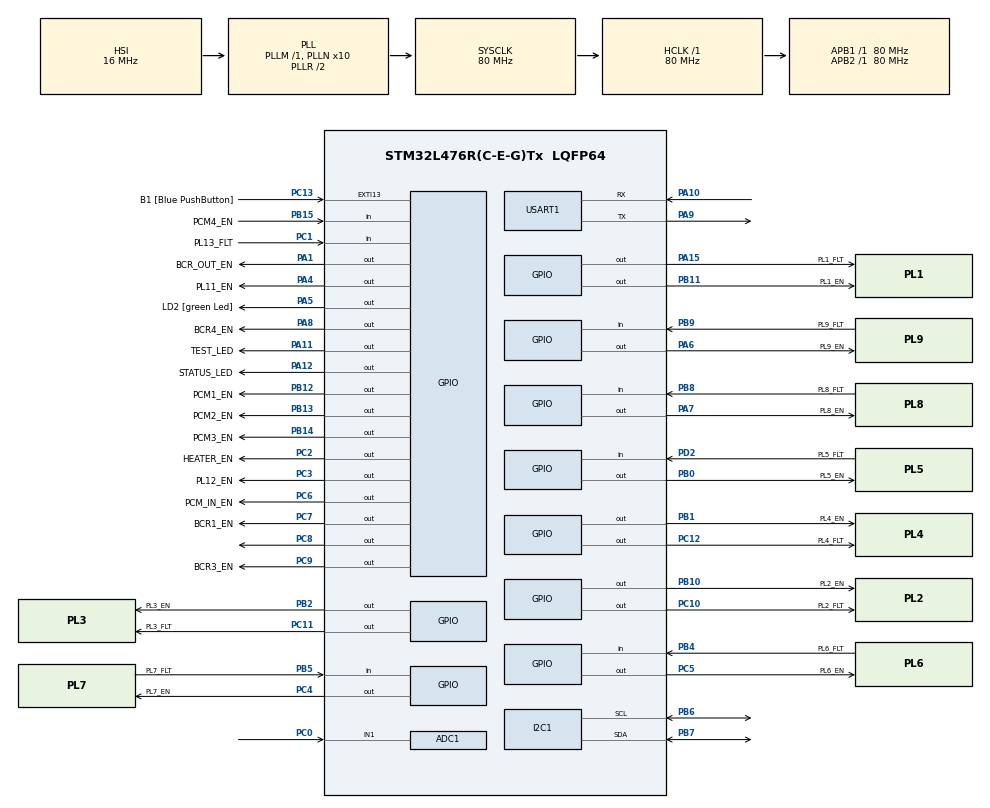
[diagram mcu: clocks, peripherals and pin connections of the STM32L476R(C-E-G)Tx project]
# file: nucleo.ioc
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ADC1.Channel-0\#ChannelRegularConversion=ADC_CHANNEL_1
ADC1.NbrOfConversionFlag=1
ADC1.OffsetNumber-0\#ChannelRegularConversion=ADC_OFFSET_NONE
ADC1.Rank-0\#ChannelRegularConversion=1
ADC1.SamplingTime-0\#ChannelRegularConversion=ADC_SAMPLETIME_2CYCLES_5
ADC1.master=1
Mcu.Family=STM32L4
Mcu.Name=STM32L476R(C-E-G)Tx
Mcu.Package=LQFP64
NVIC.PriorityGroup=NVIC_PRIORITYGROUP_4
PA0.Mode=SYS_WakeUp0
PA0.Signal=SYS_WKUP1
PA1.GPIO_Label=BCR_OUT_EN
PA1.Signal=GPIO_Output
PA10.Mode=Asynchronous
PA10.Signal=USART1_RX
PA11.GPIO_Label=TEST_LED
PA11.Signal=GPIO_Output
PA12.GPIO_Label=STATUS_LED
PA12.Signal=GPIO_Output
PA13.GPIO_Label=TMS
PA13.Signal=SYS_JTMS-SWDIO
PA14.GPIO_Label=TCK
PA14.Signal=SYS_JTCK-SWCLK
PA15.GPIO_Label=PL1_FLT
PA15.Signal=GPIO_Output
PA2.GPIO_Label=USART_TX
PA2.GPIO_Mode=GPIO_MODE_AF_PP
PA2.GPIO_PuPd=GPIO_NOPULL
PA2.GPIO_Speed=GPIO_SPEED_FREQ_VERY_HIGH
PA2.Signal=USART2_TX
PA3.GPIO_Label=USART_RX
PA3.GPIO_Mode=GPIO_MODE_AF_PP
PA3.GPIO_PuPd=GPIO_NOPULL
PA3.GPIO_Speed=GPIO_SPEED_FREQ_VERY_HIGH
PA3.Signal=USART2_RX
PA4.GPIO_Label=PL11_EN
PA4.Signal=GPIO_Output
PA5.GPIO_Label=LD2 [green Led]
PA5.GPIO_ModeDefaultOutputPP=GPIO_MODE_OUTPUT_PP
PA5.GPIO_PuPd=GPIO_NOPULL
PA5.GPIO_Speed=GPIO_SPEED_FREQ_LOW
PA5.Signal=GPIO_Output
PA6.GPIO_Label=PL9_EN
PA6.Signal=GPIO_Output
PA7.GPIO_Label=PL8_EN
PA7.Signal=GPIO_Output
PA8.GPIO_Label=BCR4_EN
PA8.Signal=GPIO_Output
PA9.Mode=Asynchronous
PA9.Signal=USART1_TX
PB0.GPIO_Label=PL5_EN
PB0.Signal=GPIO_Output
PB1.GPIO_Label=PL4_EN
PB1.Signal=GPIO_Output
PB10.GPIO_Label=PL2_EN
PB10.Signal=GPIO_Output
PB11.GPIO_Label=PL1_EN
PB11.Signal=GPIO_Output
PB12.GPIO_Label=PCM1_EN
PB12.Signal=GPIO_Output
PB13.GPIO_Label=PCM2_EN
PB13.Signal=GPIO_Output
PB14.GPIO_Label=PCM3_EN
PB14.Signal=GPIO_Output
PB15.GPIO_Label=PCM4_EN
PB15.Signal=GPIO_Input
PB2.GPIO_Label=PL3_EN
PB2.Signal=GPIO_Output
PB3.GPIO_Label=SWO
PB3.Signal=SYS_JTDO-SWO
PB4.GPIO_Label=PL6_FLT
PB4.Signal=GPIO_Input
PB5.GPIO_Label=PL7_FLT
PB5.Signal=GPIO_Input
PB6.Mode=I2C
PB6.Signal=I2C1_SCL
PB7.Mode=I2C
PB7.Signal=I2C1_SDA
PB8.GPIO_Label=PL8_FLT
PB8.Signal=GPIO_Input
PB9.GPIO_Label=PL9_FLT
PB9.Signal=GPIO_Input
PC0.Signal=ADCx_IN1
PC1.GPIO_Label=PL13_FLT
PC1.Signal=GPIO_Input
PC10.GPIO_Label=PL2_FLT
PC10.Signal=GPIO_Output
PC11.GPIO_Label=PL3_FLT
PC11.Signal=GPIO_Output
PC12.GPIO_Label=PL4_FLT
PC12.Signal=GPIO_Output
PC13.GPIO_Label=B1 [Blue PushButton]
PC13.GPIO_ModeDefaultEXTI=GPIO_MODE_IT_FALLING
PC13.GPIO_PuPd=GPIO_NOPULL
PC13.Signal=GPXTI13
PC14/OSC32_IN.Signal=RCC_OSC32_IN
PC15/OSC32_OUT.Signal=RCC_OSC32_OUT
PC2.GPIO_Label=HEATER_EN
PC2.Signal=GPIO_Output
PC3.GPIO_Label=PL12_EN
PC3.Signal=GPIO_Output
PC4.GPIO_Label=PL7_EN
PC4.Signal=GPIO_Output
PC5.GPIO_Label=PL6_EN
PC5.Signal=GPIO_Output
PC6.GPIO_Label=PCM_IN_EN
PC6.Signal=GPIO_Output
PC7.GPIO_Label=BCR1_EN
PC7.Signal=GPIO_Output
PC8.Signal=GPIO_Output
PC9.GPIO_Label=BCR3_EN
PC9.Signal=GPIO_Output
PD2.GPIO_Label=PL5_FLT
PD2.Signal=GPIO_Input
PH0/OSC_IN.Signal=RCC_OSC_IN
PH1/OSC_OUT.Signal=RCC_OSC_OUT
ProjectManager.HeapSize=0x200
ProjectManager.StackSize=0x400
ProjectManager.TargetToolchain=MDK-ARM V5
RCC.ADCFreq_Value=64000000
RCC.AHBFreq_Value=80000000
RCC.APB1Freq_Value=80000000
RCC.APB1TimFreq_Value=80000000
RCC.APB2Freq_Value=80000000
RCC.APB2TimFreq_Value=80000000
RCC.CortexFreq_Value=80000000
RCC.HCLKFreq_Value=80000000
RCC.HSE_VALUE=8000000
RCC.HSI_VALUE=16000000
RCC.LSE_VALUE=32768
RCC.MSI_VALUE=4000000
RCC.PLLN=10
RCC.PLLSourceVirtual=RCC_PLLSOURCE_HSI
RCC.PREFETCH_ENABLE=1
RCC.SYSCLKFreq_VALUE=80000000
RCC.SYSCLKSource=RCC_SYSCLKSOURCE_PLLCLK
RCC.USBFreq_Value=64000000
RCC.VCOOutputFreq_Value=160000000
SH.ADCx_IN1.0=ADC1_IN1,IN1-Single-Ended
USART1.VirtualMode-Asynchronous=VM_ASYNC
board=NUCLEO-L476RG

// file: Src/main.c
/*SEDS TRITEIA POWER SYSTEMS TEAM prototype EPS code
 *C code to implement EPS protection Schemes
 *STM32 version 0.0.1
 *Authored by Jordan Prazak and David TU
 *
 */

/**
  ******************************************************************************
  * File Name          : main.c
  * Description        : Main program body
  ******************************************************************************
  *
  * COPYRIGHT(c) 2017 STMicroelectronics
  *
  * Redistribution and use in source and binary forms, with or without modification,
  * are permitted provided that the following conditions are met:
  *   1. Redistributions of source code must retain the above copyright notice,
  *      this list of conditions and the following disclaimer.
  *   2. Redistributions in binary form must reproduce the above copyright notice,
  *      this list of conditions and the following disclaimer in the documentation
  *      and/or other materials provided with the distribution.
  *   3. Neither the name of STMicroelectronics nor the names of its contributors
  *      may be used to endorse or promote products derived from this software
  *      without specific prior written permission.
  *
  * THIS SOFTWARE IS PROVIDED BY THE COPYRIGHT HOLDERS AND CONTRIBUTORS "AS IS"
  * AND ANY EXPRESS OR IMPLIED WARRANTIES, INCLUDING, BUT NOT LIMITED TO, THE
  * IMPLIED WARRANTIES OF MERCHANTABILITY AND FITNESS FOR A PARTICULAR PURPOSE ARE
  * DISCLAIMED. IN NO EVENT SHALL THE COPYRIGHT HOLDER OR CONTRIBUTORS BE LIABLE
  * FOR ANY DIRECT, INDIRECT, INCIDENTAL, SPECIAL, EXEMPLARY, OR CONSEQUENTIAL
  * DAMAGES (INCLUDING, BUT NOT LIMITED TO, PROCUREMENT OF SUBSTITUTE GOODS OR
  * SERVICES; LOSS OF USE, DATA, OR PROFITS; OR BUSINESS INTERRUPTION) HOWEVER
  * CAUSED AND ON ANY THEORY OF LIABILITY, WHETHER IN CONTRACT, STRICT LIABILITY,
  * OR TORT (INCLUDING NEGLIGENCE OR OTHERWISE) ARISING IN ANY WAY OUT OF THE USE
  * OF THIS SOFTWARE, EVEN IF ADVISED OF THE POSSIBILITY OF SUCH DAMAGE.
  *
  ******************************************************************************
  */
#include "main.h"
#include "stm32l4xx_hal.h"

/*EPS includes ---------------------------------------------------------------*/
#include "INA260.h"
#include "EPS.h"

ADC_HandleTypeDef hadc1;

I2C_HandleTypeDef hi2c1;

UART_HandleTypeDef huart1;

void SystemClock_Config(void);
void Error_Handler(void);
static void MX_GPIO_Init(void);
static void MX_I2C1_Init(void);
static void MX_ADC1_Init(void);
static void MX_USART1_UART_Init(void);

//TODO add correct indexes for INA260 current and voltage monitoring chips
int main(void)
{
  /* MCU Configuration--------------------------------------------------------*/

  /* Reset of all peripherals, Initializes the Flash interface and the Systick*/
  HAL_Init();

  /* Configure the system clock */
  SystemClock_Config();

  /* Initialize all configured peripherals */
  MX_GPIO_Init();
  MX_I2C1_Init();
  MX_ADC1_Init();
  MX_USART1_UART_Init();

  /* Turn on LD2 */
  HAL_GPIO_WritePin(GPIOA, LD2_Pin, GPIO_PIN_SET);

	/*Initialize System --------------------------------------------------------*/
	//init variables
	// Boolean to determine whether to send data (stream) to CHREC processor
	int i;
	unsigned int streamenabled;
	EPS_status_t EPS_status;

	//configure IV monitors
 	sendConfig( &hi2c1,0);
	sendConfig( &hi2c1,1);
	sendConfig( &hi2c1,2);
	sendConfig( &hi2c1,3);
	sendConfig( &hi2c1,4);
	sendConfig( &hi2c1,5);
	sendConfig( &hi2c1,6);
	sendConfig( &hi2c1,7);
	sendConfig( &hi2c1,8);
	sendConfig( &hi2c1,9);

/*******************************************************************************
*                          EPS Power-on sequence                               *
*******************************************************************************/

	// Measure battery voltage until it comes into an acceptable range
	do {
		sendConfig( &hi2c1,0);
		EPS_status.batt_v = getVoltage(&hi2c1,0);
	} while(EPS_status.batt_v < DEPLOYED_BATT_LOW || EPS_status.batt_v > DEPLOYED_BATT_HIGH );

	// Next, check to see if there is voltage and current coming from one of the
	// solar panels. If so, the cubesat is deployed.
	do {
		sendConfig( &hi2c1,0);
		EPS_status.solar1_i = getCurrent(&hi2c1,0);
		EPS_status.solar1_v = getVoltage(&hi2c1,0);

		sendConfig( &hi2c1,0);
		EPS_status.solar2_i = getCurrent(&hi2c1,0);
		EPS_status.solar2_v = getVoltage(&hi2c1,0);

		sendConfig( &hi2c1,0);
		EPS_status.solar3_i = getCurrent(&hi2c1,0);
		EPS_status.solar3_v = getVoltage(&hi2c1,0);

		sendConfig( &hi2c1,0);
		EPS_status.solar4_i = getCurrent(&hi2c1,0);
		EPS_status.solar4_v = getVoltage(&hi2c1,0);

	} while(
			( EPS_status.solar1_v > DEPLOYED_SOLAR_V && EPS_status.solar1_i > DEPLOYED_SOLAR_I ) ||
			( EPS_status.solar2_v > DEPLOYED_SOLAR_V && EPS_status.solar2_i > DEPLOYED_SOLAR_I ) ||
			( EPS_status.solar3_v > DEPLOYED_SOLAR_V && EPS_status.solar3_i > DEPLOYED_SOLAR_I ) ||
			( EPS_status.solar4_v > DEPLOYED_SOLAR_V && EPS_status.solar4_i > DEPLOYED_SOLAR_I )
			 );

	// Cubesat has been successfully deployed. Wait at least 15 seconds, and
	// then power on all the loads.
	HAL_DELAY(15000);

	HAL_GPIO_WritePin(GPIOC, PCM_IN_EN_Pin, GPIO_PIN_SET); //enable EPS output

	}

/*******************************************************************************
*             Voltage, Current, and Temperature Monitoring                     *
*******************************************************************************/

		// Trigger a measurement on the IV monitors
 		sendConfig( &hi2c1,0);
		sendConfig( &hi2c1,1);
		sendConfig( &hi2c1,2);
		sendConfig( &hi2c1,3);
		sendConfig( &hi2c1,4);
		sendConfig( &hi2c1,5);
		sendConfig( &hi2c1,6);
		sendConfig( &hi2c1,7);
		sendConfig( &hi2c1,8);
		sendConfig( &hi2c1,9);
 		HAL_DELAY(CONVERSION_TIME_INA3221);

		EPS_status.solar1_i = getCurrent(&hi2c1,0);
		EPS_status.solar1_v = getVoltage(&hi2c1,0);

    batt_temp = (float) mmap_adc_read_raw( 0 ) * 1.8 * 1000000 / 4095 / 994 - 273.2 + TEMP_CALIBRATION;

    // Current conversion: i * 0.04/(8*2)
    // Voltage conversion: v * 0.008/8
    // 28V rail, current & voltage: i or v * 0.00125

    /**************************************************************************
     *                       Battery: Over-voltage Check                      *
     **************************************************************************/

    // If battery voltage is too high, open BCR switch
    if( batt_iv.v > BATT_OVER_VOLTAGE ) {
      gpio_set_value( BCR_OUT_EN, 0 );
    }
    else {

      // TODO we need to figure out a turn-on BCR voltage after over voltage
      gpio_set_value( BCR_OUT_EN, 1 );
    }

    /**************************************************************************
     *                       Battery: Under-voltage Check                     *
     **************************************************************************/

     // If battery voltage is too low, open PCM switch
      if( batt_iv.v < BATT_UNDER_VOLTAGE ) {
        i = 0;
        while( PDM_EN[i] != NULL ) {
          gpio_set_value( PDM_EN[i++], LOW );
        }
      }
      else {

        // TODO we need to figure out a turn-on PCM after under voltage
        i = 0;
        while( PDM_EN[i] != NULL ) {
          gpio_set_value( PDM_EN[i++], HIGH );
        }
      }

    /**************************************************************************
     *                     Power Rails: Over-current Check                    *
     **************************************************************************/

     // TODO
     // So technically, we have control of every payload.
     // Since the re-latching time is very quick, it will have no effect with
     // the 1 Hz loop code checking 3 times (3 seconds). We will need an
     // internal static counter. If after 3 seconds it's still latched, we have
     // a permanent fault.

     i = 0;
     while( PDM_FAULT[i] != NULL ) {
       if( gpio_get_value( PDM_FAULT[i] ) != 0 ) {
         if( faults[i].fault_count < 3 ) {
           // Attempt to unlatch
           gpio_set_value( PDM_EN[i], 0 );
     			 usleep( 1000 );
     			 gpio_set_value( PDM_EN[i], 1 );
           faults[i].fault_count += 1;
         }
         else {
           // PERMANENT FAULT! TODO SEND TO MISSION CONTROL! But only do it once.
           gpio_set_value( PDM_EN[i], 0 );
         }
       }
       else {
         faults[i].fault_count = 0;
       }
       i += 1;
     }

    /**************************************************************************
     *                       Battery Temperature Check                        *
     **************************************************************************/

      // If the battery temperature is too low, turn on heater until the
      // desired temperature is reached.
      if( batt_temp < HEATER_ON_TEMP ) {
        gpio_set_value( HEATER_EN, 1 );
      }
      else if( batt_temp > HEATER_OFF_TEMP ) {
        gpio_set_value( HEATER_EN, 0 );
      }

    /**************************************************************************
     *                     Sending Data to CHREC processor                    *
     **************************************************************************/
  	//send data is unused for the subsystem prototype
      // if the stream is enabled, send data to CHREK processor
      //this process may run on a separate timer instead
      //if (streamenabled==1)
          //send_data();

    // Sample at a rate of 1 Hz
  	usleep(1000000);
  }

  return EXIT_SUCCESS;
}
}
/** System Clock Configuration
*/
void SystemClock_Config(void)
{

  RCC_OscInitTypeDef RCC_OscInitStruct;
  RCC_ClkInitTypeDef RCC_ClkInitStruct;
  RCC_PeriphCLKInitTypeDef PeriphClkInit;

    /**Initializes the CPU, AHB and APB busses clocks
    */
  RCC_OscInitStruct.OscillatorType = RCC_OSCILLATORTYPE_HSI;
  RCC_OscInitStruct.HSIState = RCC_HSI_ON;
  RCC_OscInitStruct.HSICalibrationValue = 16;
  RCC_OscInitStruct.PLL.PLLState = RCC_PLL_ON;
  RCC_OscInitStruct.PLL.PLLSource = RCC_PLLSOURCE_HSI;
  RCC_OscInitStruct.PLL.PLLM = 1;
  RCC_OscInitStruct.PLL.PLLN = 10;
  RCC_OscInitStruct.PLL.PLLP = RCC_PLLP_DIV7;
  RCC_OscInitStruct.PLL.PLLQ = RCC_PLLQ_DIV2;
  RCC_OscInitStruct.PLL.PLLR = RCC_PLLR_DIV2;
  if (HAL_RCC_OscConfig(&RCC_OscInitStruct) != HAL_OK)
  {
    Error_Handler();
  }

    /**Initializes the CPU, AHB and APB busses clocks
    */
  RCC_ClkInitStruct.ClockType = RCC_CLOCKTYPE_HCLK|RCC_CLOCKTYPE_SYSCLK
                              |RCC_CLOCKTYPE_PCLK1|RCC_CLOCKTYPE_PCLK2;
  RCC_ClkInitStruct.SYSCLKSource = RCC_SYSCLKSOURCE_PLLCLK;
  RCC_ClkInitStruct.AHBCLKDivider = RCC_SYSCLK_DIV1;
  RCC_ClkInitStruct.APB1CLKDivider = RCC_HCLK_DIV1;
  RCC_ClkInitStruct.APB2CLKDivider = RCC_HCLK_DIV1;

  if (HAL_RCC_ClockConfig(&RCC_ClkInitStruct, FLASH_LATENCY_4) != HAL_OK)
  {
    Error_Handler();
  }

  PeriphClkInit.PeriphClockSelection = RCC_PERIPHCLK_USART1|RCC_PERIPHCLK_I2C1
                              |RCC_PERIPHCLK_ADC;
  PeriphClkInit.Usart1ClockSelection = RCC_USART1CLKSOURCE_PCLK2;
  PeriphClkInit.I2c1ClockSelection = RCC_I2C1CLKSOURCE_PCLK1;
  PeriphClkInit.AdcClockSelection = RCC_ADCCLKSOURCE_PLLSAI1;
  PeriphClkInit.PLLSAI1.PLLSAI1Source = RCC_PLLSOURCE_HSI;
  PeriphClkInit.PLLSAI1.PLLSAI1M = 1;
  PeriphClkInit.PLLSAI1.PLLSAI1N = 8;
  PeriphClkInit.PLLSAI1.PLLSAI1P = RCC_PLLP_DIV7;
  PeriphClkInit.PLLSAI1.PLLSAI1Q = RCC_PLLQ_DIV2;
  PeriphClkInit.PLLSAI1.PLLSAI1R = RCC_PLLR_DIV2;
  PeriphClkInit.PLLSAI1.PLLSAI1ClockOut = RCC_PLLSAI1_ADC1CLK;
  if (HAL_RCCEx_PeriphCLKConfig(&PeriphClkInit) != HAL_OK)
  {
    Error_Handler();
  }

    /**Configure the main internal regulator output voltage
    */
  if (HAL_PWREx_ControlVoltageScaling(PWR_REGULATOR_VOLTAGE_SCALE1) != HAL_OK)
  {
    Error_Handler();
  }

    /**Configure the Systick interrupt time
    */
  HAL_SYSTICK_Config(HAL_RCC_GetHCLKFreq()/1000);

    /**Configure the Systick
    */
  HAL_SYSTICK_CLKSourceConfig(SYSTICK_CLKSOURCE_HCLK);

  /* SysTick_IRQn interrupt configuration */
  HAL_NVIC_SetPriority(SysTick_IRQn, 0, 0);
}

/* ADC1 init function */
static void MX_ADC1_Init(void)
{

  ADC_MultiModeTypeDef multimode;
  ADC_ChannelConfTypeDef sConfig;

    /**Common config
    */
  hadc1.Instance = ADC1;
  hadc1.Init.ClockPrescaler = ADC_CLOCK_ASYNC_DIV1;
  hadc1.Init.Resolution = ADC_RESOLUTION_12B;
  hadc1.Init.DataAlign = ADC_DATAALIGN_RIGHT;
  hadc1.Init.ScanConvMode = ADC_SCAN_DISABLE;
  hadc1.Init.EOCSelection = ADC_EOC_SINGLE_CONV;
  hadc1.Init.LowPowerAutoWait = DISABLE;
  hadc1.Init.ContinuousConvMode = DISABLE;
  hadc1.Init.NbrOfConversion = 1;
  hadc1.Init.DiscontinuousConvMode = DISABLE;
  hadc1.Init.NbrOfDiscConversion = 1;
  hadc1.Init.ExternalTrigConv = ADC_SOFTWARE_START;
  hadc1.Init.ExternalTrigConvEdge = ADC_EXTERNALTRIGCONVEDGE_NONE;
  hadc1.Init.DMAContinuousRequests = DISABLE;
  hadc1.Init.Overrun = ADC_OVR_DATA_PRESERVED;
  hadc1.Init.OversamplingMode = DISABLE;
  if (HAL_ADC_Init(&hadc1) != HAL_OK)
  {
    Error_Handler();
  }

    /**Configure the ADC multi-mode
    */
  multimode.Mode = ADC_MODE_INDEPENDENT;
  if (HAL_ADCEx_MultiModeConfigChannel(&hadc1, &multimode) != HAL_OK)
  {
    Error_Handler();
  }

    /**Configure Regular Channel
    */
  sConfig.Channel = ADC_CHANNEL_1;
  sConfig.Rank = 1;
  sConfig.SamplingTime = ADC_SAMPLETIME_2CYCLES_5;
  sConfig.SingleDiff = ADC_SINGLE_ENDED;
  sConfig.OffsetNumber = ADC_OFFSET_NONE;
  sConfig.Offset = 0;
  if (HAL_ADC_ConfigChannel(&hadc1, &sConfig) != HAL_OK)
  {
    Error_Handler();
  }

}

/* I2C1 init function */
static void MX_I2C1_Init(void)
{

  hi2c1.Instance = I2C1;
  hi2c1.Init.Timing = 0x10909CEC;
  hi2c1.Init.OwnAddress1 = 0;
  hi2c1.Init.AddressingMode = I2C_ADDRESSINGMODE_7BIT;
  hi2c1.Init.DualAddressMode = I2C_DUALADDRESS_DISABLE;
  hi2c1.Init.OwnAddress2 = 0;
  hi2c1.Init.OwnAddress2Masks = I2C_OA2_NOMASK;
  hi2c1.Init.GeneralCallMode = I2C_GENERALCALL_DISABLE;
  hi2c1.Init.NoStretchMode = I2C_NOSTRETCH_DISABLE;
  if (HAL_I2C_Init(&hi2c1) != HAL_OK)
  {
    Error_Handler();
  }

    /**Configure Analogue filter
    */
  if (HAL_I2CEx_ConfigAnalogFilter(&hi2c1, I2C_ANALOGFILTER_ENABLE) != HAL_OK)
  {
    Error_Handler();
  }

    /**Configure Digital filter
    */
  if (HAL_I2CEx_ConfigDigitalFilter(&hi2c1, 0) != HAL_OK)
  {
    Error_Handler();
  }

}

/* USART1 init function */
static void MX_USART1_UART_Init(void)
{

  huart1.Instance = USART1;
  huart1.Init.BaudRate = 115200;
  huart1.Init.WordLength = UART_WORDLENGTH_7B;
  huart1.Init.StopBits = UART_STOPBITS_1;
  huart1.Init.Parity = UART_PARITY_NONE;
  huart1.Init.Mode = UART_MODE_TX_RX;
  huart1.Init.HwFlowCtl = UART_HWCONTROL_NONE;
  huart1.Init.OverSampling = UART_OVERSAMPLING_16;
  huart1.Init.OneBitSampling = UART_ONE_BIT_SAMPLE_DISABLE;
  huart1.AdvancedInit.AdvFeatureInit = UART_ADVFEATURE_NO_INIT;
  if (HAL_UART_Init(&huart1) != HAL_OK)
  {
    Error_Handler();
  }

}

/** Configure pins as
        * Analog
        * Input
        * Output
        * EVENT_OUT
        * EXTI
     PA2   ------> USART2_TX
     PA3   ------> USART2_RX
*/
static void MX_GPIO_Init(void)
{

  GPIO_InitTypeDef GPIO_InitStruct;

  /* GPIO Ports Clock Enable */
  __HAL_RCC_GPIOC_CLK_ENABLE();
  __HAL_RCC_GPIOH_CLK_ENABLE();
  __HAL_RCC_GPIOA_CLK_ENABLE();
  __HAL_RCC_GPIOB_CLK_ENABLE();
  __HAL_RCC_GPIOD_CLK_ENABLE();

  /*Configure GPIO pin Output Level */
  HAL_GPIO_WritePin(GPIOC, HEATER_EN_Pin|PL12_EN_Pin|PL7_EN_Pin|PL6_EN_Pin
                          |PCM_IN_EN_Pin|BCR1_EN_Pin|GPIO_PIN_8|BCR3_EN_Pin
                          |PL2_FLT_Pin|PL3_FLT_Pin|PL4_FLT_Pin, GPIO_PIN_RESET);

  /*Configure GPIO pin Output Level */
  HAL_GPIO_WritePin(GPIOA, BCR_OUT_EN_Pin|PL11_EN_Pin|LD2_Pin|PL9_EN_Pin
                          |PL8_EN_Pin|BCR4_EN_Pin|TEST_LED_Pin|STATUS_LED_Pin
                          |PL1_FLT_Pin, GPIO_PIN_RESET);

  /*Configure GPIO pin Output Level */
  HAL_GPIO_WritePin(GPIOB, PL5_EN_Pin|PL4_EN_Pin|PL3_EN_Pin|PL2_EN_Pin
                          |PL1_EN_Pin|PCM1_EN_Pin|PCM2_EN_Pin|PCM3_EN_Pin, GPIO_PIN_RESET);

  /*Configure GPIO pin : B1_Pin */
  GPIO_InitStruct.Pin = B1_Pin;
  GPIO_InitStruct.Mode = GPIO_MODE_IT_FALLING;
  GPIO_InitStruct.Pull = GPIO_NOPULL;
  HAL_GPIO_Init(B1_GPIO_Port, &GPIO_InitStruct);

  /*Configure GPIO pin : PL13_FLT_Pin */
  GPIO_InitStruct.Pin = PL13_FLT_Pin;
  GPIO_InitStruct.Mode = GPIO_MODE_INPUT;
  GPIO_InitStruct.Pull = GPIO_NOPULL;
  HAL_GPIO_Init(PL13_FLT_GPIO_Port, &GPIO_InitStruct);

  /*Configure GPIO pins : HEATER_EN_Pin PL12_EN_Pin PL7_EN_Pin PL6_EN_Pin
                           PCM_IN_EN_Pin BCR1_EN_Pin PC8 BCR3_EN_Pin
                           PL2_FLT_Pin PL3_FLT_Pin PL4_FLT_Pin */
  GPIO_InitStruct.Pin = HEATER_EN_Pin|PL12_EN_Pin|PL7_EN_Pin|PL6_EN_Pin
                          |PCM_IN_EN_Pin|BCR1_EN_Pin|GPIO_PIN_8|BCR3_EN_Pin
                          |PL2_FLT_Pin|PL3_FLT_Pin|PL4_FLT_Pin;
  GPIO_InitStruct.Mode = GPIO_MODE_OUTPUT_PP;
  GPIO_InitStruct.Pull = GPIO_NOPULL;
  GPIO_InitStruct.Speed = GPIO_SPEED_FREQ_LOW;
  HAL_GPIO_Init(GPIOC, &GPIO_InitStruct);

  /*Configure GPIO pins : BCR_OUT_EN_Pin PL11_EN_Pin LD2_Pin PL9_EN_Pin
                           PL8_EN_Pin BCR4_EN_Pin TEST_LED_Pin STATUS_LED_Pin
                           PL1_FLT_Pin */
  GPIO_InitStruct.Pin = BCR_OUT_EN_Pin|PL11_EN_Pin|LD2_Pin|PL9_EN_Pin
                          |PL8_EN_Pin|BCR4_EN_Pin|TEST_LED_Pin|STATUS_LED_Pin
                          |PL1_FLT_Pin;
  GPIO_InitStruct.Mode = GPIO_MODE_OUTPUT_PP;
  GPIO_InitStruct.Pull = GPIO_NOPULL;
  GPIO_InitStruct.Speed = GPIO_SPEED_FREQ_LOW;
  HAL_GPIO_Init(GPIOA, &GPIO_InitStruct);

  /*Configure GPIO pins : USART_TX_Pin USART_RX_Pin */
  GPIO_InitStruct.Pin = USART_TX_Pin|USART_RX_Pin;
  GPIO_InitStruct.Mode = GPIO_MODE_AF_PP;
  GPIO_InitStruct.Pull = GPIO_NOPULL;
  GPIO_InitStruct.Speed = GPIO_SPEED_FREQ_VERY_HIGH;
  GPIO_InitStruct.Alternate = GPIO_AF7_USART2;
  HAL_GPIO_Init(GPIOA, &GPIO_InitStruct);

  /*Configure GPIO pins : PL5_EN_Pin PL4_EN_Pin PL3_EN_Pin PL2_EN_Pin
                           PL1_EN_Pin PCM1_EN_Pin PCM2_EN_Pin PCM3_EN_Pin */
  GPIO_InitStruct.Pin = PL5_EN_Pin|PL4_EN_Pin|PL3_EN_Pin|PL2_EN_Pin
                          |PL1_EN_Pin|PCM1_EN_Pin|PCM2_EN_Pin|PCM3_EN_Pin;
  GPIO_InitStruct.Mode = GPIO_MODE_OUTPUT_PP;
  GPIO_InitStruct.Pull = GPIO_NOPULL;
  GPIO_InitStruct.Speed = GPIO_SPEED_FREQ_LOW;
  HAL_GPIO_Init(GPIOB, &GPIO_InitStruct);

  /*Configure GPIO pins : PCM4_EN_Pin PL6_FLT_Pin PL7_FLT_Pin PL8_FLT_Pin
                           PL9_FLT_Pin */
  GPIO_InitStruct.Pin = PCM4_EN_Pin|PL6_FLT_Pin|PL7_FLT_Pin|PL8_FLT_Pin
                          |PL9_FLT_Pin;
  GPIO_InitStruct.Mode = GPIO_MODE_INPUT;
  GPIO_InitStruct.Pull = GPIO_NOPULL;
  HAL_GPIO_Init(GPIOB, &GPIO_InitStruct);

  /*Configure GPIO pin : PL5_FLT_Pin */
  GPIO_InitStruct.Pin = PL5_FLT_Pin;
  GPIO_InitStruct.Mode = GPIO_MODE_INPUT;
  GPIO_InitStruct.Pull = GPIO_NOPULL;
  HAL_GPIO_Init(PL5_FLT_GPIO_Port, &GPIO_InitStruct);

}

/* USER CODE BEGIN 4 */
/* Called when a read is completed - works on interrupt */
void HAL_UART_RxCpltCallback(UART_HandleTypeDef *huart)
{
  /* Prevent unused argument(s) compilation warning */
  UNUSED(huart);

  /* NOTE : This function should not be modified, when the callback is needed,
            the HAL_UART_RxCpltCallback can be implemented in the user file.
   */
}

/* USER CODE END 4 */

void Error_Handler(void)
{
  while(1)
  {
  }
}

/************************ (C) COPYRIGHT STMicroelectronics *****END OF FILE****/
